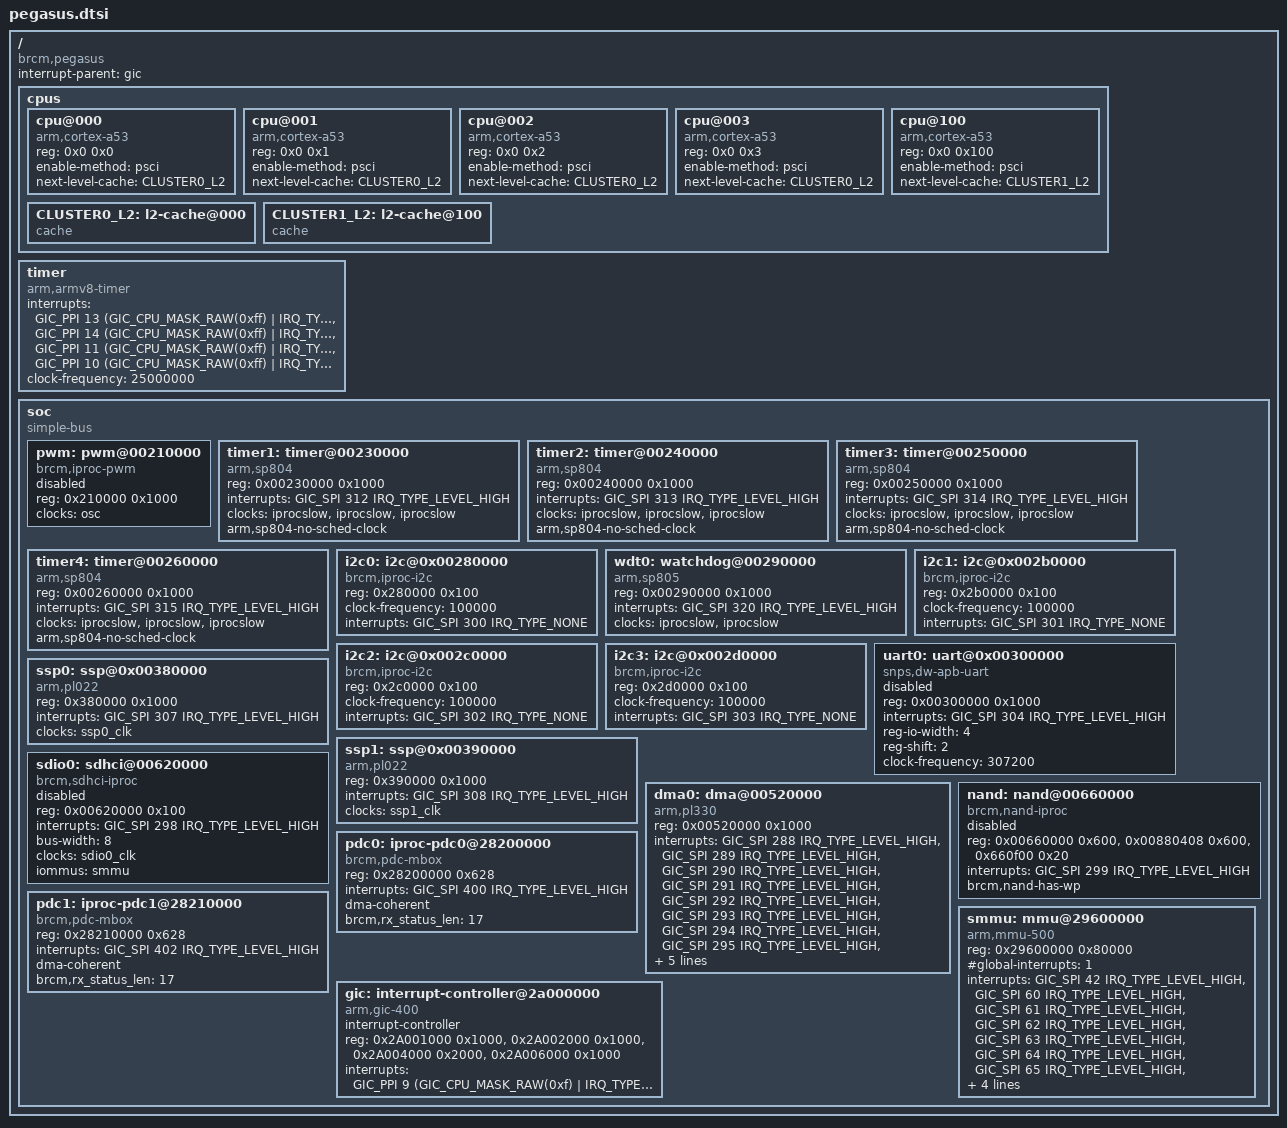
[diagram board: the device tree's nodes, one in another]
/*
 *  BSD LICENSE
 *
 *  Copyright(c) 2015 Broadcom Corporation.  All rights reserved.
 *
 *  Redistribution and use in source and binary forms, with or without
 *  modification, are permitted provided that the following conditions
 *  are met:
 *
 *    * Redistributions of source code must retain the above copyright
 *      notice, this list of conditions and the following disclaimer.
 *    * Redistributions in binary form must reproduce the above copyright
 *      notice, this list of conditions and the following disclaimer in
 *      the documentation and/or other materials provided with the
 *      distribution.
 *    * Neither the name of Broadcom Corporation nor the names of its
 *      contributors may be used to endorse or promote products derived
 *      from this software without specific prior written permission.
 *
 *  THIS SOFTWARE IS PROVIDED BY THE COPYRIGHT HOLDERS AND CONTRIBUTORS
 *  "AS IS" AND ANY EXPRESS OR IMPLIED WARRANTIES, INCLUDING, BUT NOT
 *  LIMITED TO, THE IMPLIED WARRANTIES OF MERCHANTABILITY AND FITNESS FOR
 *  A PARTICULAR PURPOSE ARE DISCLAIMED. IN NO EVENT SHALL THE COPYRIGHT
 *  OWNER OR CONTRIBUTORS BE LIABLE FOR ANY DIRECT, INDIRECT, INCIDENTAL,
 *  SPECIAL, EXEMPLARY, OR CONSEQUENTIAL DAMAGES (INCLUDING, BUT NOT
 *  LIMITED TO, PROCUREMENT OF SUBSTITUTE GOODS OR SERVICES; LOSS OF USE,
 *  DATA, OR PROFITS; OR BUSINESS INTERRUPTION) HOWEVER CAUSED AND ON ANY
 *  THEORY OF LIABILITY, WHETHER IN CONTRACT, STRICT LIABILITY, OR TORT
 *  (INCLUDING NEGLIGENCE OR OTHERWISE) ARISING IN ANY WAY OUT OF THE USE
 * OF THIS SOFTWARE, EVEN IF ADVISED OF THE POSSIBILITY OF SUCH DAMAGE.
 */

#include <dt-bindings/interrupt-controller/arm-gic.h>

/ {
	compatible = "brcm,pegasus";
	interrupt-parent = <&gic>;
	#address-cells = <2>;
	#size-cells = <2>;

	cpus {
		#address-cells = <2>;
		#size-cells = <0>;

		cpu@000 {
			device_type = "cpu";
			compatible = "arm,cortex-a53", "arm,armv8";
			reg = <0x0 0x0>;
			enable-method = "psci";
			next-level-cache = <&CLUSTER0_L2>;
		};

		cpu@001 {
			device_type = "cpu";
			compatible = "arm,cortex-a53", "arm,armv8";
			reg = <0x0 0x1>;
			enable-method = "psci";
			next-level-cache = <&CLUSTER0_L2>;
		};

		cpu@002 {
			device_type = "cpu";
			compatible = "arm,cortex-a53", "arm,armv8";
			reg = <0x0 0x2>;
			enable-method = "psci";
			next-level-cache = <&CLUSTER0_L2>;
		};

		cpu@003 {
			device_type = "cpu";
			compatible = "arm,cortex-a53", "arm,armv8";
			reg = <0x0 0x3>;
			enable-method = "psci";
			next-level-cache = <&CLUSTER0_L2>;
		};

		cpu@100 {
			device_type = "cpu";
			compatible = "arm,cortex-a53","arm,armv8";
			reg = <0x0 0x100>;
			enable-method = "psci";
			next-level-cache = <&CLUSTER1_L2>;
		};

		CLUSTER0_L2: l2-cache@000 {
			compatible = "cache";
		};

		CLUSTER1_L2: l2-cache@100 {
			compatible = "cache";
		};
	};

	timer {
		compatible = "arm,armv8-timer";
		interrupts = <GIC_PPI 13 (GIC_CPU_MASK_RAW(0xff) |
					IRQ_TYPE_EDGE_RISING)>,
			     <GIC_PPI 14 (GIC_CPU_MASK_RAW(0xff) |
					IRQ_TYPE_EDGE_RISING)>,
			     <GIC_PPI 11 (GIC_CPU_MASK_RAW(0xff) |
					IRQ_TYPE_EDGE_RISING)>,
			     <GIC_PPI 10 (GIC_CPU_MASK_RAW(0xff) |
					IRQ_TYPE_EDGE_RISING)>;
		clock-frequency = <25000000>;
	};

	soc {
		compatible = "simple-bus";
		#address-cells = <1>;
		#size-cells = <1>;
		ranges = <0 0 0 0xffffffff>;

		#include "pegasus-clock.dtsi"

		pwm: pwm@00210000 {
			compatible = "brcm,iproc-pwm";
			reg = <0x210000 0x1000>;
			clocks = <&osc>;
			#pwm-cells = <3>;
			status = "disabled";
		};

		timer1: timer@00230000 {
			compatible = "arm,sp804", "arm,primecell";
			reg = <0x00230000 0x1000>;
			interrupts = <GIC_SPI 312 IRQ_TYPE_LEVEL_HIGH>;
			clocks = <&iprocslow>,
				 <&iprocslow>,
				 <&iprocslow>;
			clock-names = "timer1", "timer2", "apb_pclk";
			arm,sp804-no-sched-clock;
		};

		timer2: timer@00240000 {
			compatible = "arm,sp804", "arm,primecell";
			reg = <0x00240000 0x1000>;
			interrupts = <GIC_SPI 313 IRQ_TYPE_LEVEL_HIGH>;
			clocks = <&iprocslow>,
				 <&iprocslow>,
				 <&iprocslow>;
			clock-names = "timer1", "timer2", "apb_pclk";
			arm,sp804-no-sched-clock;
		};

		timer3: timer@00250000 {
			compatible = "arm,sp804", "arm,primecell";
			reg = <0x00250000 0x1000>;
			interrupts = <GIC_SPI 314 IRQ_TYPE_LEVEL_HIGH>;
			clocks = <&iprocslow>,
				 <&iprocslow>,
				 <&iprocslow>;
			clock-names = "timer1", "timer2", "apb_pclk";
			arm,sp804-no-sched-clock;
		};

		timer4: timer@00260000 {
			compatible = "arm,sp804", "arm,primecell";
			reg = <0x00260000 0x1000>;
			interrupts = <GIC_SPI 315 IRQ_TYPE_LEVEL_HIGH>;
			clocks = <&iprocslow>,
				 <&iprocslow>,
				 <&iprocslow>;
			clock-names = "timer1", "timer2", "apb_pclk";
			arm,sp804-no-sched-clock;
		};

		i2c0: i2c@0x00280000 {
			compatible = "brcm,iproc-i2c";
			reg = <0x280000 0x100>;
			clock-frequency = <100000>;
			interrupts = <GIC_SPI 300 IRQ_TYPE_NONE>;
		};

		wdt0: watchdog@00290000 {
			compatible = "arm,sp805", "arm,primecell";
			reg = <0x00290000 0x1000>;
			interrupts = <GIC_SPI 320 IRQ_TYPE_LEVEL_HIGH>;
			clocks = <&iprocslow>, <&iprocslow>;
			clock-names = "wdogclk", "apb_pclk";
		};

		i2c1: i2c@0x002b0000 {
			compatible = "brcm,iproc-i2c";
			reg = <0x2b0000 0x100>;
			clock-frequency = <100000>;
			interrupts = <GIC_SPI 301 IRQ_TYPE_NONE>;
		};

		i2c2: i2c@0x002c0000 {
			compatible = "brcm,iproc-i2c";
			reg = <0x2c0000 0x100>;
			clock-frequency = <100000>;
			interrupts = <GIC_SPI 302 IRQ_TYPE_NONE>;
		};

		i2c3: i2c@0x002d0000 {
			compatible = "brcm,iproc-i2c";
			reg = <0x2d0000 0x100>;
			clock-frequency = <100000>;
			interrupts = <GIC_SPI 303 IRQ_TYPE_NONE>;
		};

		uart0: uart@0x00300000 {
			device_type = "serial";
			compatible = "snps,dw-apb-uart";
			reg = <0x00300000 0x1000>;
			interrupts = <GIC_SPI 304 IRQ_TYPE_LEVEL_HIGH>;
			reg-io-width = <4>;
			reg-shift = <2>;
			clock-frequency = <307200>;
			status = "disabled";
		};

		ssp0: ssp@0x00380000 {
			compatible = "arm,pl022", "arm,primecell";
			reg = <0x380000 0x1000>;
			interrupts = <GIC_SPI 307 IRQ_TYPE_LEVEL_HIGH>;
			clocks = <&ssp0_clk>;
			clock-names = "apb_pclk";
		};

		ssp1: ssp@0x00390000 {
			compatible = "arm,pl022", "arm,primecell";
			reg = <0x390000 0x1000>;
			interrupts = <GIC_SPI 308 IRQ_TYPE_LEVEL_HIGH>;
			clocks = <&ssp1_clk>;
			clock-names = "apb_pclk";
		};

		dma0: dma@00520000 {
			compatible = "arm,pl330", "arm,primecell";
			reg = <0x00520000 0x1000>;
			interrupts = <GIC_SPI 288 IRQ_TYPE_LEVEL_HIGH>,
					<GIC_SPI 289 IRQ_TYPE_LEVEL_HIGH>,
					<GIC_SPI 290 IRQ_TYPE_LEVEL_HIGH>,
					<GIC_SPI 291 IRQ_TYPE_LEVEL_HIGH>,
					<GIC_SPI 292 IRQ_TYPE_LEVEL_HIGH>,
					<GIC_SPI 293 IRQ_TYPE_LEVEL_HIGH>,
					<GIC_SPI 294 IRQ_TYPE_LEVEL_HIGH>,
					<GIC_SPI 295 IRQ_TYPE_LEVEL_HIGH>,
					<GIC_SPI 296 IRQ_TYPE_LEVEL_HIGH>;
			#dma-cells = <1>;
			#dma-channels = <8>;
			#dma-requests = <32>;
			clocks = <&iprocslow>;
			clock-names = "apb_pclk";
			#stream-id-cells = <1>;
			iommus = <&smmu>;
		};

		sdio0: sdhci@00620000 {
			compatible = "brcm,sdhci-iproc";
			reg = <0x00620000 0x100>;
			interrupts = <GIC_SPI 298 IRQ_TYPE_LEVEL_HIGH>;
			bus-width = <8>;
			clocks = <&sdio0_clk>;
			#stream-id-cells = <1>;
			iommus = <&smmu>;
			status = "disabled";
		};

		nand: nand@00660000 {
			compatible = "brcm,nand-iproc", "brcm,brcmnand-v6.1";
			reg = <0x00660000 0x600>,
			      <0x00880408 0x600>,
			      <0x660f00 0x20>;
			reg-names = "nand", "iproc-idm", "iproc-ext";
			interrupts = <GIC_SPI 299 IRQ_TYPE_LEVEL_HIGH>;
			#address-cells = <1>;
			#size-cells = <0>;
			brcm,nand-has-wp;
			status = "disabled";
		};

		pdc0: iproc-pdc0@28200000 {
			compatible = "brcm,pdc-mbox";
			reg = <0x28200000 0x628>;
			interrupts = <GIC_SPI 400 IRQ_TYPE_LEVEL_HIGH>;
			#mbox-cells = <1>;
			dma-coherent;
			brcm,rx_status_len = <17>;
		};

		pdc1: iproc-pdc1@28210000 {
			compatible = "brcm,pdc-mbox";
			reg = <0x28210000 0x628>;
			interrupts = <GIC_SPI 402 IRQ_TYPE_LEVEL_HIGH>;
			#mbox-cells = <1>;
			dma-coherent;
			brcm,rx_status_len = <17>;
		};

		gic: interrupt-controller@2a000000 {
			compatible = "arm,gic-400";
			#interrupt-cells = <3>;
			interrupt-controller;
			reg = <0x2A001000 0x1000>,
				<0x2A002000 0x1000>,
				<0x2A004000 0x2000>,
				<0x2A006000 0x1000>;
			interrupts = <GIC_PPI 9 (GIC_CPU_MASK_RAW(0xf) |
					IRQ_TYPE_LEVEL_HIGH)>;
		};

		smmu: mmu@29600000 {
			compatible = "arm,mmu-500";
			reg = <0x29600000 0x80000>;
			#global-interrupts = <1>;
			interrupts = <GIC_SPI 42 IRQ_TYPE_LEVEL_HIGH>,
				     <GIC_SPI 60 IRQ_TYPE_LEVEL_HIGH>,
				     <GIC_SPI 61 IRQ_TYPE_LEVEL_HIGH>,
				     <GIC_SPI 62 IRQ_TYPE_LEVEL_HIGH>,
				     <GIC_SPI 63 IRQ_TYPE_LEVEL_HIGH>,
				     <GIC_SPI 64 IRQ_TYPE_LEVEL_HIGH>,
				     <GIC_SPI 65 IRQ_TYPE_LEVEL_HIGH>,
				     <GIC_SPI 66 IRQ_TYPE_LEVEL_HIGH>,
				     <GIC_SPI 67 IRQ_TYPE_LEVEL_HIGH>;
			mmu-masters = <&dma0 0x6000>,
				      <&sdio0 0x6001>;
			smmu-inst-as-data;
			#iommu-cells = <0>;
		};
	};
};
